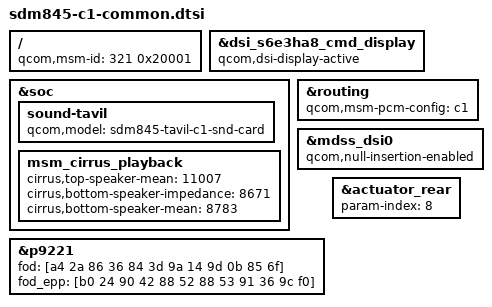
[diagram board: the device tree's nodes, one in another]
/* Copyright (c) 2017 Google, Inc.
 *
 * This software is licensed under the terms of the GNU General Public
 * License version 2, as published by the Free Software Foundation, and
 * may be copied, distributed, and modified under those terms.
 *
 * This program is distributed in the hope that it will be useful,
 * but WITHOUT ANY WARRANTY; without even the implied warranty of
 * MERCHANTABILITY or FITNESS FOR A PARTICULAR PURPOSE.  See the
 * GNU General Public License for more details.
 *
 */

#include "sdm845-b1c1-common.dtsi"

#include "sdm845-c1-touch.dtsi"
#include "sdm845-b1c1-audio.dtsi"
#include "sdm845-c1-battery.dtsi"

/ {
	qcom,msm-id = <321 0x20001>;
};

&dsi_s6e3ha8_cmd_display {
	qcom,dsi-display-active;
};

/* This overylay is required in order for acdbloader to load different files */
&soc {
	sound-tavil {
		qcom,model = "sdm845-tavil-c1-snd-card";
	};

	msm_cirrus_playback {
		/* the resistance is 7.8698 ohm */
		cirrus,top-speaker-mean = <11007>;

		/* the resistance is 6.1996 ohm */
		cirrus,bottom-speaker-impedance = <8671>;

		/* the resistance is 6.276 ohm */
		cirrus,bottom-speaker-mean = <8783>;
	};
};

&routing {
	qcom,msm-pcm-config = "c1";
};

&mdss_dsi0 {
	qcom,null-insertion-enabled;
};

&p9221 {
	fod = [a4 2a 86 36 84 3d 9a 14 9d 0b 85 6f];
	fod_epp = [b0 24 90 42 88 52 88 53 91 36 9c f0];
};

&actuator_rear {
	param-index = <8>;
};
